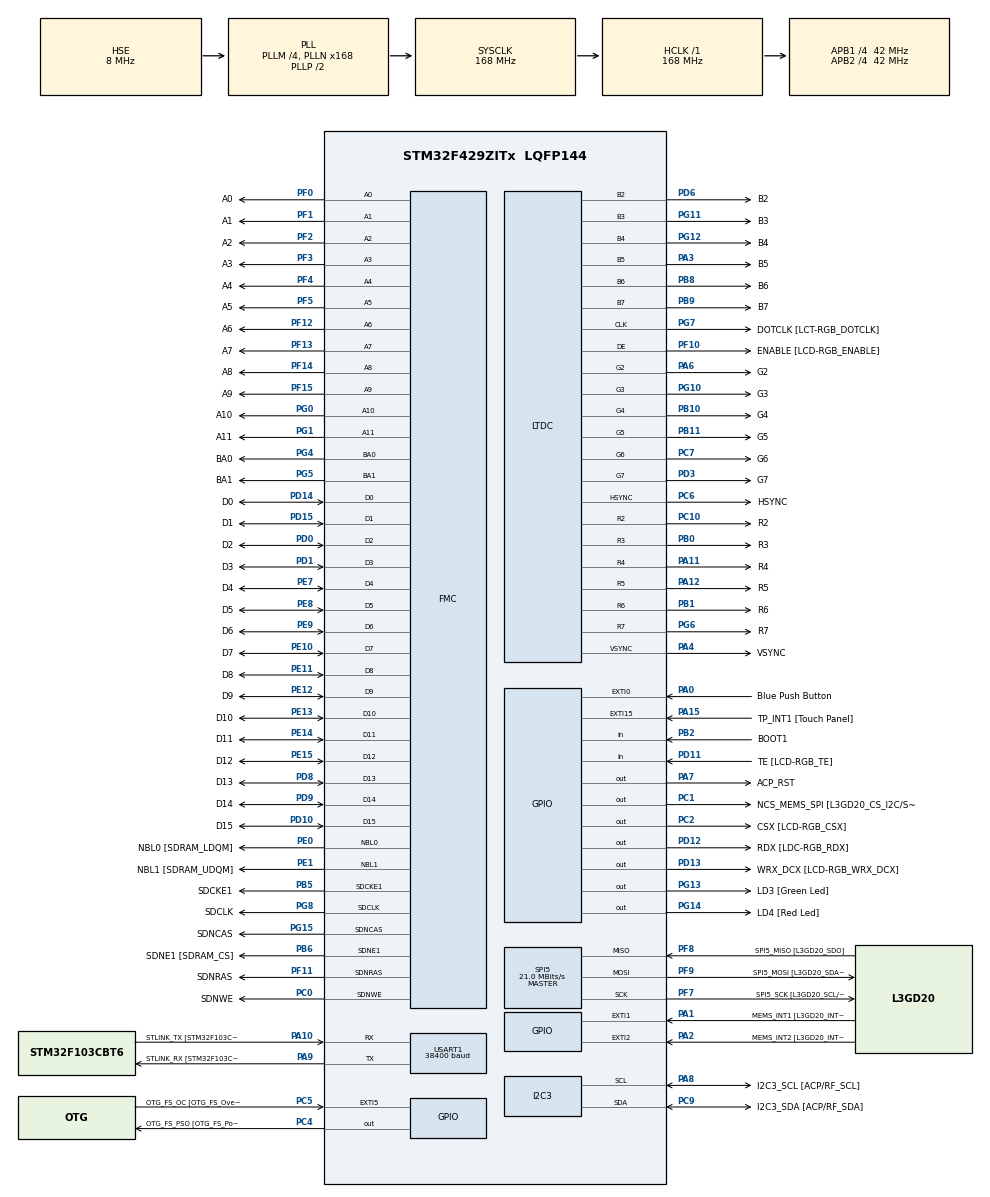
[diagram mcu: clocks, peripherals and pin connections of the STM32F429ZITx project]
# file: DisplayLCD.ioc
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DMA2D.ColorMode=DMA2D_OUTPUT_RGB565
FREERTOS.BinarySemaphores01=sensores,Dynamic,NULL;touch,Dynamic,NULL
FREERTOS.Tasks01=PrintaDisplay,0,128,StartPrintaDisplay,Default,NULL,Dynamic,NULL,NULL;MonitoraTouch,0,128,StartMonitoraTouch,Default,NULL,Dynamic,NULL,NULL
LTDC.ActiveH=240
LTDC.ActiveW=320
Mcu.Family=STM32F4
Mcu.Name=STM32F429ZITx
Mcu.Package=LQFP144
NVIC.EXTI0_IRQn=true\:5\:0\:false\:false\:true\:true\:true
NVIC.PriorityGroup=NVIC_PRIORITYGROUP_4
NVIC.TIM1_UP_TIM10_IRQn=true\:0\:0\:false\:false\:true\:false\:false
NVIC.TimeBase=TIM1_UP_TIM10_IRQn
NVIC.TimeBaseIP=TIM1
NVIC.USART1_IRQn=true\:5\:0\:false\:false\:true\:true\:true
PA0/WKUP.GPIO_Label=Blue Push Button
PA0/WKUP.GPIO_ModeDefaultEXTI=GPIO_MODE_IT_RISING
PA0/WKUP.Signal=GPXTI0
PA1.GPIO_Label=MEMS_INT1 [L3GD20_INT1]
PA1.GPIO_ModeDefaultEXTI=GPIO_MODE_EVT_RISING
PA1.GPIO_PuPd=GPIO_NOPULL
PA1.Signal=GPXTI1
PA10.GPIO_Label=STLINK_TX [STM32F103CBT6_PA2]
PA10.Mode=Asynchronous
PA10.Signal=USART1_RX
PA11.GPIO_Label=R4
PA11.GPIO_Mode=GPIO_MODE_AF_PP
PA11.GPIO_PuPd=GPIO_NOPULL
PA11.GPIO_Speed=GPIO_SPEED_FREQ_LOW
PA11.Mode=RGB666
PA11.Signal=LTDC_R4
PA12.GPIO_Label=R5
PA12.GPIO_Mode=GPIO_MODE_AF_PP
PA12.GPIO_PuPd=GPIO_NOPULL
PA12.GPIO_Speed=GPIO_SPEED_FREQ_LOW
PA12.Mode=RGB666
PA12.Signal=LTDC_R5
PA13.GPIO_Label=SWDIO
PA13.Mode=Serial_Wire
PA13.Signal=SYS_JTMS-SWDIO
PA14.GPIO_Label=SWCLK
PA14.Mode=Serial_Wire
PA14.Signal=SYS_JTCK-SWCLK
PA15.GPIO_Label=TP_INT1 [Touch Panel]
PA15.GPIO_ModeDefaultEXTI=GPIO_MODE_EVT_RISING
PA15.GPIO_PuPd=GPIO_NOPULL
PA15.Signal=GPXTI15
PA2.GPIO_Label=MEMS_INT2 [L3GD20_INT2]
PA2.GPIO_ModeDefaultEXTI=GPIO_MODE_EVT_RISING
PA2.GPIO_PuPd=GPIO_NOPULL
PA2.Signal=GPXTI2
PA3.GPIO_Label=B5
PA3.GPIO_Mode=GPIO_MODE_AF_PP
PA3.GPIO_PuPd=GPIO_NOPULL
PA3.GPIO_Speed=GPIO_SPEED_FREQ_LOW
PA3.Mode=RGB666
PA3.Signal=LTDC_B5
PA4.GPIO_Label=VSYNC
PA4.GPIO_Mode=GPIO_MODE_AF_PP
PA4.GPIO_PuPd=GPIO_NOPULL
PA4.GPIO_Speed=GPIO_SPEED_FREQ_LOW
PA4.Mode=RGB666
PA4.Signal=LTDC_VSYNC
PA6.GPIO_Label=G2
PA6.GPIO_Mode=GPIO_MODE_AF_PP
PA6.GPIO_PuPd=GPIO_NOPULL
PA6.GPIO_Speed=GPIO_SPEED_FREQ_LOW
PA6.Mode=RGB666
PA6.Signal=LTDC_G2
PA7.GPIO_Label=ACP_RST
PA7.GPIO_Mode=GPIO_MODE_OUTPUT_PP
PA7.GPIO_PuPd=GPIO_NOPULL
PA7.GPIO_Speed=GPIO_SPEED_FREQ_LOW
PA7.Signal=GPIO_Output
PA8.GPIO_Label=I2C3_SCL [ACP/RF_SCL]
PA8.GPIO_Mode=GPIO_MODE_AF_OD
PA8.GPIO_PuPd=GPIO_NOPULL
PA8.GPIO_Speed=GPIO_SPEED_FREQ_LOW
PA8.Mode=I2C
PA8.Signal=I2C3_SCL
PA9.GPIO_Label=STLINK_RX [STM32F103CBT6_PA3]
PA9.Mode=Asynchronous
PA9.Signal=USART1_TX
PB0.GPIO_Label=R3
PB0.GPIO_Mode=GPIO_MODE_AF_PP
PB0.GPIO_PuPd=GPIO_NOPULL
PB0.GPIO_Speed=GPIO_SPEED_FREQ_LOW
PB0.Mode=RGB666
PB0.Signal=LTDC_R3
PB1.GPIO_Label=R6
PB1.GPIO_Mode=GPIO_MODE_AF_PP
PB1.GPIO_PuPd=GPIO_NOPULL
PB1.GPIO_Speed=GPIO_SPEED_FREQ_LOW
PB1.Mode=RGB666
PB1.Signal=LTDC_R6
PB10.GPIO_Label=G4
PB10.GPIO_Mode=GPIO_MODE_AF_PP
PB10.GPIO_PuPd=GPIO_NOPULL
PB10.GPIO_Speed=GPIO_SPEED_FREQ_LOW
PB10.Mode=RGB666
PB10.Signal=LTDC_G4
PB11.GPIO_Label=G5
PB11.GPIO_Mode=GPIO_MODE_AF_PP
PB11.GPIO_PuPd=GPIO_NOPULL
PB11.GPIO_Speed=GPIO_SPEED_FREQ_LOW
PB11.Mode=RGB666
PB11.Signal=LTDC_G5
PB12.GPIO_Label=OTG_HS_ID
PB12.GPIO_Mode=GPIO_MODE_AF_PP
PB12.GPIO_PuPd=GPIO_NOPULL
PB12.GPIO_Speed=GPIO_SPEED_FREQ_LOW
PB12.Signal=USB_OTG_HS_ID
PB13.GPIO_Label=VBUS_HS
PB13.GPIO_Mode=GPIO_MODE_INPUT
PB13.GPIO_PuPd=GPIO_NOPULL
PB13.Signal=USB_OTG_HS_VBUS
PB14.GPIO_Label=OTG_HS_DM
PB14.GPIO_Mode=GPIO_MODE_AF_PP
PB14.GPIO_PuPd=GPIO_NOPULL
PB14.GPIO_Speed=GPIO_SPEED_FREQ_LOW
PB14.Signal=USB_OTG_HS_DM
PB15.GPIO_Label=OTG_HS_DP
PB15.GPIO_Mode=GPIO_MODE_AF_PP
PB15.GPIO_PuPd=GPIO_NOPULL
PB15.GPIO_Speed=GPIO_SPEED_FREQ_LOW
PB15.Signal=USB_OTG_HS_DP
PB2/BOOT1.GPIO_Label=BOOT1
PB2/BOOT1.GPIO_Mode=GPIO_MODE_INPUT
PB2/BOOT1.GPIO_PuPd=GPIO_NOPULL
PB2/BOOT1.Signal=GPIO_Input
PB5.GPIO_Label=SDCKE1
PB5.GPIO_Mode=GPIO_MODE_AF_PP
PB5.GPIO_PuPd=GPIO_NOPULL
PB5.GPIO_Speed=GPIO_SPEED_FREQ_VERY_HIGH
PB5.Mode=SdramChipSelect2_1
PB5.Signal=FMC_SDCKE1
PB6.GPIO_Label=SDNE1 [SDRAM_CS]
PB6.GPIO_Mode=GPIO_MODE_AF_PP
PB6.GPIO_PuPd=GPIO_NOPULL
PB6.GPIO_Speed=GPIO_SPEED_FREQ_VERY_HIGH
PB6.Mode=SdramChipSelect2_1
PB6.Signal=FMC_SDNE1
PB8.GPIO_Label=B6
PB8.GPIO_Mode=GPIO_MODE_AF_PP
PB8.GPIO_PuPd=GPIO_NOPULL
PB8.GPIO_Speed=GPIO_SPEED_FREQ_LOW
PB8.Mode=RGB666
PB8.Signal=LTDC_B6
PB9.GPIO_Label=B7
PB9.GPIO_Mode=GPIO_MODE_AF_PP
PB9.GPIO_PuPd=GPIO_NOPULL
PB9.GPIO_Speed=GPIO_SPEED_FREQ_LOW
PB9.Mode=RGB666
PB9.Signal=LTDC_B7
PC0.GPIO_Label=SDNWE
PC0.GPIO_Mode=GPIO_MODE_AF_PP
PC0.GPIO_PuPd=GPIO_NOPULL
PC0.GPIO_Speed=GPIO_SPEED_FREQ_VERY_HIGH
PC0.Signal=FMC_SDNWE
PC1.GPIO_Label=NCS_MEMS_SPI [L3GD20_CS_I2C/SPI]
PC1.GPIO_Mode=GPIO_MODE_OUTPUT_PP
PC1.GPIO_PuPd=GPIO_NOPULL
PC1.GPIO_Speed=GPIO_SPEED_FREQ_LOW
PC1.Signal=GPIO_Output
PC10.GPIO_Label=R2
PC10.GPIO_Mode=GPIO_MODE_AF_PP
PC10.GPIO_PuPd=GPIO_NOPULL
PC10.GPIO_Speed=GPIO_SPEED_FREQ_LOW
PC10.Mode=RGB666
PC10.Signal=LTDC_R2
PC14/OSC32_IN.GPIO_Label=PC14-OSC32_IN
PC14/OSC32_IN.Signal=RCC_OSC32_IN
PC15/OSC32_OUT.GPIO_Label=PC15-OSC32_OUT
PC15/OSC32_OUT.Signal=RCC_OSC32_OUT
PC2.GPIO_Label=CSX [LCD-RGB_CSX]
PC2.GPIO_Mode=GPIO_MODE_OUTPUT_PP
PC2.GPIO_PuPd=GPIO_NOPULL
PC2.GPIO_Speed=GPIO_SPEED_FREQ_LOW
PC2.Signal=GPIO_Output
PC4.GPIO_Label=OTG_FS_PSO [OTG_FS_PowerSwitchOn]
PC4.GPIO_Mode=GPIO_MODE_OUTPUT_PP
PC4.GPIO_PuPd=GPIO_NOPULL
PC4.GPIO_Speed=GPIO_SPEED_FREQ_LOW
PC4.Signal=GPIO_Output
PC5.GPIO_Label=OTG_FS_OC [OTG_FS_OverCurrent]
PC5.GPIO_ModeDefaultEXTI=GPIO_MODE_EVT_RISING
PC5.Signal=GPXTI5
PC6.GPIO_Label=HSYNC
PC6.GPIO_Mode=GPIO_MODE_AF_PP
PC6.GPIO_PuPd=GPIO_NOPULL
PC6.GPIO_Speed=GPIO_SPEED_FREQ_LOW
PC6.Mode=RGB666
PC6.Signal=LTDC_HSYNC
PC7.GPIO_Label=G6
PC7.GPIO_Mode=GPIO_MODE_AF_PP
PC7.GPIO_PuPd=GPIO_NOPULL
PC7.GPIO_Speed=GPIO_SPEED_FREQ_LOW
PC7.Mode=RGB666
PC7.Signal=LTDC_G6
PC9.GPIO_Label=I2C3_SDA [ACP/RF_SDA]
PC9.GPIO_Mode=GPIO_MODE_AF_OD
PC9.GPIO_PuPd=GPIO_NOPULL
PC9.GPIO_Speed=GPIO_SPEED_FREQ_LOW
PC9.Mode=I2C
PC9.Signal=I2C3_SDA
PD0.GPIO_Label=D2
PD0.GPIO_Mode=GPIO_MODE_AF_PP
PD0.GPIO_PuPd=GPIO_NOPULL
PD0.GPIO_Speed=GPIO_SPEED_FREQ_VERY_HIGH
PD0.Signal=FMC_D2_DA2
PD1.GPIO_Label=D3
PD1.GPIO_Mode=GPIO_MODE_AF_PP
PD1.GPIO_PuPd=GPIO_NOPULL
PD1.GPIO_Speed=GPIO_SPEED_FREQ_VERY_HIGH
PD1.Signal=FMC_D3_DA3
PD10.GPIO_Label=D15
PD10.GPIO_Mode=GPIO_MODE_AF_PP
PD10.GPIO_PuPd=GPIO_NOPULL
PD10.GPIO_Speed=GPIO_SPEED_FREQ_VERY_HIGH
PD10.Signal=FMC_D15_DA15
PD11.GPIO_Label=TE [LCD-RGB_TE]
PD11.GPIO_Mode=GPIO_MODE_INPUT
PD11.GPIO_PuPd=GPIO_NOPULL
PD11.Signal=GPIO_Input
PD12.GPIO_Label=RDX [LDC-RGB_RDX]
PD12.GPIO_Mode=GPIO_MODE_OUTPUT_PP
PD12.GPIO_PuPd=GPIO_NOPULL
PD12.GPIO_Speed=GPIO_SPEED_FREQ_LOW
PD12.Signal=GPIO_Output
PD13.GPIO_Label=WRX_DCX [LCD-RGB_WRX_DCX]
PD13.GPIO_Mode=GPIO_MODE_OUTPUT_PP
PD13.GPIO_PuPd=GPIO_NOPULL
PD13.GPIO_Speed=GPIO_SPEED_FREQ_LOW
PD13.Signal=GPIO_Output
PD14.GPIO_Label=D0
PD14.GPIO_Mode=GPIO_MODE_AF_PP
PD14.GPIO_PuPd=GPIO_NOPULL
PD14.GPIO_Speed=GPIO_SPEED_FREQ_VERY_HIGH
PD14.Signal=FMC_D0_DA0
PD15.GPIO_Label=D1
PD15.GPIO_Mode=GPIO_MODE_AF_PP
PD15.GPIO_PuPd=GPIO_NOPULL
PD15.GPIO_Speed=GPIO_SPEED_FREQ_VERY_HIGH
PD15.Signal=FMC_D1_DA1
PD3.GPIO_Label=G7
PD3.GPIO_Mode=GPIO_MODE_AF_PP
PD3.GPIO_PuPd=GPIO_NOPULL
PD3.GPIO_Speed=GPIO_SPEED_FREQ_LOW
PD3.Mode=RGB666
PD3.Signal=LTDC_G7
PD6.GPIO_Label=B2
PD6.GPIO_Mode=GPIO_MODE_AF_PP
PD6.GPIO_PuPd=GPIO_NOPULL
PD6.GPIO_Speed=GPIO_SPEED_FREQ_LOW
PD6.Mode=RGB666
PD6.Signal=LTDC_B2
PD8.GPIO_Label=D13
PD8.GPIO_Mode=GPIO_MODE_AF_PP
PD8.GPIO_PuPd=GPIO_NOPULL
PD8.GPIO_Speed=GPIO_SPEED_FREQ_VERY_HIGH
PD8.Signal=FMC_D13_DA13
PD9.GPIO_Label=D14
PD9.GPIO_Mode=GPIO_MODE_AF_PP
PD9.GPIO_PuPd=GPIO_NOPULL
PD9.GPIO_Speed=GPIO_SPEED_FREQ_VERY_HIGH
PD9.Signal=FMC_D14_DA14
PE0.GPIO_Label=NBL0 [SDRAM_LDQM]
PE0.GPIO_Mode=GPIO_MODE_AF_PP
PE0.GPIO_PuPd=GPIO_NOPULL
PE0.GPIO_Speed=GPIO_SPEED_FREQ_VERY_HIGH
PE0.Signal=FMC_NBL0
PE1.GPIO_Label=NBL1 [SDRAM_UDQM]
PE1.GPIO_Mode=GPIO_MODE_AF_PP
PE1.GPIO_PuPd=GPIO_NOPULL
PE1.GPIO_Speed=GPIO_SPEED_FREQ_VERY_HIGH
PE1.Signal=FMC_NBL1
PE10.GPIO_Label=D7
PE10.GPIO_Mode=GPIO_MODE_AF_PP
PE10.GPIO_PuPd=GPIO_NOPULL
PE10.GPIO_Speed=GPIO_SPEED_FREQ_VERY_HIGH
PE10.Signal=FMC_D7_DA7
PE11.GPIO_Label=D8
PE11.GPIO_Mode=GPIO_MODE_AF_PP
PE11.GPIO_PuPd=GPIO_NOPULL
PE11.GPIO_Speed=GPIO_SPEED_FREQ_VERY_HIGH
PE11.Signal=FMC_D8_DA8
PE12.GPIO_Label=D9
PE12.GPIO_Mode=GPIO_MODE_AF_PP
PE12.GPIO_PuPd=GPIO_NOPULL
PE12.GPIO_Speed=GPIO_SPEED_FREQ_VERY_HIGH
PE12.Signal=FMC_D9_DA9
PE13.GPIO_Label=D10
PE13.GPIO_Mode=GPIO_MODE_AF_PP
PE13.GPIO_PuPd=GPIO_NOPULL
PE13.GPIO_Speed=GPIO_SPEED_FREQ_VERY_HIGH
PE13.Signal=FMC_D10_DA10
PE14.GPIO_Label=D11
PE14.GPIO_Mode=GPIO_MODE_AF_PP
PE14.GPIO_PuPd=GPIO_NOPULL
PE14.GPIO_Speed=GPIO_SPEED_FREQ_VERY_HIGH
PE14.Signal=FMC_D11_DA11
PE15.GPIO_Label=D12
PE15.GPIO_Mode=GPIO_MODE_AF_PP
PE15.GPIO_PuPd=GPIO_NOPULL
PE15.GPIO_Speed=GPIO_SPEED_FREQ_VERY_HIGH
PE15.Signal=FMC_D12_DA12
PE7.GPIO_Label=D4
PE7.GPIO_Mode=GPIO_MODE_AF_PP
PE7.GPIO_PuPd=GPIO_NOPULL
PE7.GPIO_Speed=GPIO_SPEED_FREQ_VERY_HIGH
PE7.Signal=FMC_D4_DA4
PE8.GPIO_Label=D5
PE8.GPIO_Mode=GPIO_MODE_AF_PP
PE8.GPIO_PuPd=GPIO_NOPULL
PE8.GPIO_Speed=GPIO_SPEED_FREQ_VERY_HIGH
PE8.Signal=FMC_D5_DA5
PE9.GPIO_Label=D6
PE9.GPIO_Mode=GPIO_MODE_AF_PP
PE9.GPIO_PuPd=GPIO_NOPULL
PE9.GPIO_Speed=GPIO_SPEED_FREQ_VERY_HIGH
PE9.Signal=FMC_D6_DA6
PF0.GPIO_Label=A0
PF0.GPIO_Mode=GPIO_MODE_AF_PP
PF0.GPIO_PuPd=GPIO_NOPULL
PF0.GPIO_Speed=GPIO_SPEED_FREQ_VERY_HIGH
PF0.Signal=FMC_A0
PF1.GPIO_Label=A1
PF1.GPIO_Mode=GPIO_MODE_AF_PP
PF1.GPIO_PuPd=GPIO_NOPULL
PF1.GPIO_Speed=GPIO_SPEED_FREQ_VERY_HIGH
PF1.Signal=FMC_A1
PF10.GPIO_Label=ENABLE [LCD-RGB_ENABLE]
PF10.GPIO_Mode=GPIO_MODE_AF_PP
PF10.GPIO_PuPd=GPIO_NOPULL
PF10.GPIO_Speed=GPIO_SPEED_FREQ_LOW
PF10.Mode=RGB666
PF10.Signal=LTDC_DE
PF11.GPIO_Label=SDNRAS
PF11.GPIO_Mode=GPIO_MODE_AF_PP
PF11.GPIO_PuPd=GPIO_NOPULL
PF11.GPIO_Speed=GPIO_SPEED_FREQ_VERY_HIGH
PF11.Signal=FMC_SDNRAS
PF12.GPIO_Label=A6
PF12.GPIO_Mode=GPIO_MODE_AF_PP
PF12.GPIO_PuPd=GPIO_NOPULL
PF12.GPIO_Speed=GPIO_SPEED_FREQ_VERY_HIGH
PF12.Signal=FMC_A6
PF13.GPIO_Label=A7
PF13.GPIO_Mode=GPIO_MODE_AF_PP
PF13.GPIO_PuPd=GPIO_NOPULL
PF13.GPIO_Speed=GPIO_SPEED_FREQ_VERY_HIGH
PF13.Signal=FMC_A7
PF14.GPIO_Label=A8
PF14.GPIO_Mode=GPIO_MODE_AF_PP
PF14.GPIO_PuPd=GPIO_NOPULL
PF14.GPIO_Speed=GPIO_SPEED_FREQ_VERY_HIGH
PF14.Signal=FMC_A8
PF15.GPIO_Label=A9
PF15.GPIO_Mode=GPIO_MODE_AF_PP
PF15.GPIO_PuPd=GPIO_NOPULL
PF15.GPIO_Speed=GPIO_SPEED_FREQ_VERY_HIGH
PF15.Signal=FMC_A9
PF2.GPIO_Label=A2
PF2.GPIO_Mode=GPIO_MODE_AF_PP
PF2.GPIO_PuPd=GPIO_NOPULL
PF2.GPIO_Speed=GPIO_SPEED_FREQ_VERY_HIGH
PF2.Signal=FMC_A2
PF3.GPIO_Label=A3
PF3.GPIO_Mode=GPIO_MODE_AF_PP
PF3.GPIO_PuPd=GPIO_NOPULL
PF3.GPIO_Speed=GPIO_SPEED_FREQ_VERY_HIGH
PF3.Signal=FMC_A3
PF4.GPIO_Label=A4
PF4.GPIO_Mode=GPIO_MODE_AF_PP
PF4.GPIO_PuPd=GPIO_NOPULL
PF4.GPIO_Speed=GPIO_SPEED_FREQ_VERY_HIGH
PF4.Signal=FMC_A4
PF5.GPIO_Label=A5
PF5.GPIO_Mode=GPIO_MODE_AF_PP
PF5.GPIO_PuPd=GPIO_NOPULL
PF5.GPIO_Speed=GPIO_SPEED_FREQ_VERY_HIGH
PF5.Signal=FMC_A5
PF7.GPIO_Label=SPI5_SCK [L3GD20_SCL/SPC]
PF7.GPIO_Mode=GPIO_MODE_AF_PP
PF7.GPIO_PuPd=GPIO_NOPULL
PF7.GPIO_Speed=GPIO_SPEED_FREQ_LOW
PF7.Mode=Full_Duplex_Master
PF7.Signal=SPI5_SCK
PF8.GPIO_Label=SPI5_MISO [L3GD20_SDO]
PF8.GPIO_Mode=GPIO_MODE_AF_PP
PF8.GPIO_PuPd=GPIO_NOPULL
PF8.GPIO_Speed=GPIO_SPEED_FREQ_LOW
PF8.Mode=Full_Duplex_Master
PF8.Signal=SPI5_MISO
PF9.GPIO_Label=SPI5_MOSI [L3GD20_SDA/SDI/SDO]
PF9.GPIO_Mode=GPIO_MODE_AF_PP
PF9.GPIO_PuPd=GPIO_NOPULL
PF9.GPIO_Speed=GPIO_SPEED_FREQ_LOW
PF9.Mode=Full_Duplex_Master
PF9.Signal=SPI5_MOSI
PG0.GPIO_Label=A10
PG0.GPIO_Mode=GPIO_MODE_AF_PP
PG0.GPIO_PuPd=GPIO_NOPULL
PG0.GPIO_Speed=GPIO_SPEED_FREQ_VERY_HIGH
PG0.Signal=FMC_A10
PG1.GPIO_Label=A11
PG1.GPIO_Mode=GPIO_MODE_AF_PP
PG1.GPIO_PuPd=GPIO_NOPULL
PG1.GPIO_Speed=GPIO_SPEED_FREQ_VERY_HIGH
PG1.Signal=FMC_A11
PG10.GPIO_Label=G3
PG10.GPIO_Mode=GPIO_MODE_AF_PP
PG10.GPIO_PuPd=GPIO_NOPULL
PG10.GPIO_Speed=GPIO_SPEED_FREQ_LOW
PG10.Mode=RGB666
PG10.Signal=LTDC_G3
PG11.GPIO_Label=B3
PG11.GPIO_Mode=GPIO_MODE_AF_PP
PG11.GPIO_PuPd=GPIO_NOPULL
PG11.GPIO_Speed=GPIO_SPEED_FREQ_LOW
PG11.Mode=RGB666
PG11.Signal=LTDC_B3
PG12.GPIO_Label=B4
PG12.GPIO_Mode=GPIO_MODE_AF_PP
PG12.GPIO_PuPd=GPIO_NOPULL
PG12.GPIO_Speed=GPIO_SPEED_FREQ_LOW
PG12.Mode=RGB666
PG12.Signal=LTDC_B4
PG13.GPIO_Label=LD3 [Green Led]
PG13.GPIO_Mode=GPIO_MODE_OUTPUT_PP
PG13.GPIO_PuPd=GPIO_NOPULL
PG13.GPIO_Speed=GPIO_SPEED_FREQ_LOW
PG13.Signal=GPIO_Output
PG14.GPIO_Label=LD4 [Red Led]
PG14.GPIO_Mode=GPIO_MODE_OUTPUT_PP
PG14.GPIO_PuPd=GPIO_NOPULL
PG14.GPIO_Speed=GPIO_SPEED_FREQ_LOW
PG14.Signal=GPIO_Output
PG15.GPIO_Label=SDNCAS
PG15.GPIO_Mode=GPIO_MODE_AF_PP
PG15.GPIO_PuPd=GPIO_NOPULL
PG15.GPIO_Speed=GPIO_SPEED_FREQ_VERY_HIGH
PG15.Signal=FMC_SDNCAS
PG4.GPIO_Label=BA0
PG4.GPIO_Mode=GPIO_MODE_AF_PP
PG4.GPIO_PuPd=GPIO_NOPULL
PG4.GPIO_Speed=GPIO_SPEED_FREQ_VERY_HIGH
PG4.Signal=FMC_A14_BA0
PG5.GPIO_Label=BA1
PG5.GPIO_Mode=GPIO_MODE_AF_PP
PG5.GPIO_PuPd=GPIO_NOPULL
PG5.GPIO_Speed=GPIO_SPEED_FREQ_VERY_HIGH
PG5.Signal=FMC_A15_BA1
PG6.GPIO_Label=R7
PG6.GPIO_Mode=GPIO_MODE_AF_PP
PG6.GPIO_PuPd=GPIO_NOPULL
PG6.GPIO_Speed=GPIO_SPEED_FREQ_LOW
PG6.Mode=RGB666
PG6.Signal=LTDC_R7
PG7.GPIO_Label=DOTCLK [LCT-RGB_DOTCLK]
PG7.GPIO_Mode=GPIO_MODE_AF_PP
PG7.GPIO_PuPd=GPIO_NOPULL
PG7.GPIO_Speed=GPIO_SPEED_FREQ_LOW
PG7.Mode=RGB666
PG7.Signal=LTDC_CLK
PG8.GPIO_Label=SDCLK
PG8.GPIO_Mode=GPIO_MODE_AF_PP
PG8.GPIO_PuPd=GPIO_NOPULL
PG8.GPIO_Speed=GPIO_SPEED_FREQ_VERY_HIGH
PG8.Signal=FMC_SDCLK
PH0/OSC_IN.GPIO_Label=PH0-OSC_IN
PH0/OSC_IN.Mode=HSE-External-Oscillator
PH0/OSC_IN.Signal=RCC_OSC_IN
PH1/OSC_OUT.GPIO_Label=PH1-OSC_OUT
PH1/OSC_OUT.Mode=HSE-External-Oscillator
PH1/OSC_OUT.Signal=RCC_OSC_OUT
ProjectManager.HeapSize=0x200
ProjectManager.StackSize=0x400
ProjectManager.TargetToolchain=MDK-ARM V5
RCC.48MHZClocksFreq_Value=48000000
RCC.AHBFreq_Value=168000000
RCC.APB1CLKDivider=RCC_HCLK_DIV4
RCC.APB1Freq_Value=42000000
RCC.APB1TimFreq_Value=84000000
RCC.APB2CLKDivider=RCC_HCLK_DIV4
RCC.APB2Freq_Value=42000000
RCC.APB2TimFreq_Value=84000000
RCC.CortexFreq_Value=168000000
RCC.HCLKFreq_Value=168000000
RCC.HSE_VALUE=8000000
RCC.HSI_VALUE=16000000
RCC.LSE_VALUE=32768
RCC.PLLM=4
RCC.PLLN=168
RCC.PLLQ=7
RCC.PLLSAIN=216
RCC.PLLSourceVirtual=RCC_PLLSOURCE_HSE
RCC.SYSCLKFreq_VALUE=168000000
RCC.SYSCLKSource=RCC_SYSCLKSOURCE_PLLCLK
RCC.VCOOutputFreq_Value=336000000
SH.FMC_A0.0=FMC_A0,12b-sda1
SH.FMC_A1.0=FMC_A1,12b-sda1
SH.FMC_A10.0=FMC_A10,12b-sda1
SH.FMC_A11.0=FMC_A11,12b-sda1
SH.FMC_A14_BA0.0=FMC_BA0,FourSdramBanks1
SH.FMC_A15_BA1.0=FMC_BA1,FourSdramBanks1
SH.FMC_A2.0=FMC_A2,12b-sda1
SH.FMC_A3.0=FMC_A3,12b-sda1
SH.FMC_A4.0=FMC_A4,12b-sda1
SH.FMC_A5.0=FMC_A5,12b-sda1
SH.FMC_A6.0=FMC_A6,12b-sda1
SH.FMC_A7.0=FMC_A7,12b-sda1
SH.FMC_A8.0=FMC_A8,12b-sda1
SH.FMC_A9.0=FMC_A9,12b-sda1
SH.FMC_D0_DA0.0=FMC_D0,sd-16b-d1
SH.FMC_D10_DA10.0=FMC_D10,sd-16b-d1
SH.FMC_D11_DA11.0=FMC_D11,sd-16b-d1
SH.FMC_D12_DA12.0=FMC_D12,sd-16b-d1
SH.FMC_D13_DA13.0=FMC_D13,sd-16b-d1
SH.FMC_D14_DA14.0=FMC_D14,sd-16b-d1
SH.FMC_D15_DA15.0=FMC_D15,sd-16b-d1
SH.FMC_D1_DA1.0=FMC_D1,sd-16b-d1
SH.FMC_D2_DA2.0=FMC_D2,sd-16b-d1
SH.FMC_D3_DA3.0=FMC_D3,sd-16b-d1
SH.FMC_D4_DA4.0=FMC_D4,sd-16b-d1
SH.FMC_D5_DA5.0=FMC_D5,sd-16b-d1
SH.FMC_D6_DA6.0=FMC_D6,sd-16b-d1
SH.FMC_D7_DA7.0=FMC_D7,sd-16b-d1
SH.FMC_D8_DA8.0=FMC_D8,sd-16b-d1
SH.FMC_D9_DA9.0=FMC_D9,sd-16b-d1
SH.FMC_NBL0.0=FMC_NBL0,Sd2ByteEnable1
SH.FMC_NBL1.0=FMC_NBL1,Sd2ByteEnable1
SH.FMC_SDCLK.0=FMC_SDCLK,12b-sda1
SH.FMC_SDNCAS.0=FMC_SDNCAS,12b-sda1
SH.FMC_SDNRAS.0=FMC_SDNRAS,12b-sda1
SH.FMC_SDNWE.0=FMC_SDNWE,12b-sda1
SPI5.CalculateBaudRate=21.0 MBits/s
SPI5.Direction=SPI_DIRECTION_2LINES
SPI5.Mode=SPI_MODE_MASTER
SPI5.VirtualType=VM_MASTER
USART1.BaudRate=38400
USART1.VirtualMode=VM_ASYNC
VP_DMA2D_VS_DMA2D.Mode=DMA2D_Activate
VP_FREERTOS_VS_ENABLE.Mode=Enabled
VP_SYS_VS_tim1.Mode=TIM1
board=32F429IDISCOVERY

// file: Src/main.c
/* USER CODE BEGIN Header */
/**
  ******************************************************************************
  * @file           : main.c
  * @brief          : Main program body
  ******************************************************************************
  ** This notice applies to any and all portions of this file
  * that are not between comment pairs USER CODE BEGIN and
  * USER CODE END. Other portions of this file, whether
  * inserted by the user or by software development tools
  * are owned by their respective copyright owners.
  *
  * COPYRIGHT(c) 2019 STMicroelectronics
  *
  * Redistribution and use in source and binary forms, with or without modification,
  * are permitted provided that the following conditions are met:
  *   1. Redistributions of source code must retain the above copyright notice,
  *      this list of conditions and the following disclaimer.
  *   2. Redistributions in binary form must reproduce the above copyright notice,
  *      this list of conditions and the following disclaimer in the documentation
  *      and/or other materials provided with the distribution.
  *   3. Neither the name of STMicroelectronics nor the names of its contributors
  *      may be used to endorse or promote products derived from this software
  *      without specific prior written permission.
  *
  * THIS SOFTWARE IS PROVIDED BY THE COPYRIGHT HOLDERS AND CONTRIBUTORS "AS IS"
  * AND ANY EXPRESS OR IMPLIED WARRANTIES, INCLUDING, BUT NOT LIMITED TO, THE
  * IMPLIED WARRANTIES OF MERCHANTABILITY AND FITNESS FOR A PARTICULAR PURPOSE ARE
  * DISCLAIMED. IN NO EVENT SHALL THE COPYRIGHT HOLDER OR CONTRIBUTORS BE LIABLE
  * FOR ANY DIRECT, INDIRECT, INCIDENTAL, SPECIAL, EXEMPLARY, OR CONSEQUENTIAL
  * DAMAGES (INCLUDING, BUT NOT LIMITED TO, PROCUREMENT OF SUBSTITUTE GOODS OR
  * SERVICES; LOSS OF USE, DATA, OR PROFITS; OR BUSINESS INTERRUPTION) HOWEVER
  * CAUSED AND ON ANY THEORY OF LIABILITY, WHETHER IN CONTRACT, STRICT LIABILITY,
  * OR TORT (INCLUDING NEGLIGENCE OR OTHERWISE) ARISING IN ANY WAY OUT OF THE USE
  * OF THIS SOFTWARE, EVEN IF ADVISED OF THE POSSIBILITY OF SUCH DAMAGE.
  *
  ******************************************************************************
  */
/* USER CODE END Header */

#include "main.h"
#include "cmsis_os.h"
#include "dma2d.h"
#include "i2c.h"
#include "ltdc.h"
#include "spi.h"
#include "usart.h"
#include "gpio.h"
#include "fmc.h"

/* USER CODE BEGIN Includes */
#include "stm32f429i_discovery_lcd.h"
#include "stm32f429i_discovery_sdram.h"
#include "stm32f429i_discovery_ts.h"
#include "string.h"
/* USER CODE END Includes */

void SystemClock_Config(void);
void MX_FREERTOS_Init(void);

int main(void)
{

  /* MCU Configuration--------------------------------------------------------*/

  /* Reset of all peripherals, Initializes the Flash interface and the Systick. */
  HAL_Init();

  /* Configure the system clock */
  SystemClock_Config();

  /* Initialize all configured peripherals */
  MX_GPIO_Init();
  MX_DMA2D_Init();
  MX_I2C3_Init();
  MX_LTDC_Init();
  MX_SPI5_Init();
  MX_FMC_Init();
  MX_USART1_UART_Init();
  /* USER CODE BEGIN 2 */

	BSP_LCD_Init();
	BSP_LCD_LayerDefaultInit(LCD_BACKGROUND_LAYER,LCD_FRAME_BUFFER);
	BSP_LCD_LayerDefaultInit(LCD_FOREGROUND_LAYER,LCD_FRAME_BUFFER);
	BSP_LCD_SelectLayer(LCD_FOREGROUND_LAYER);
	BSP_LCD_DisplayOn();
	BSP_LCD_Clear(LCD_COLOR_WHITE);
	BSP_LCD_SetTextColor(LCD_COLOR_RED);
	BSP_TS_Init(240, 320);

  /* USER CODE END 2 */

  /* Call init function for freertos objects (in freertos.c) */
  MX_FREERTOS_Init();

  /* Start scheduler */
  osKernelStart();

  /* We should never get here as control is now taken by the scheduler */

  /* Infinite loop */
  while (1)
  {

    /* USER CODE BEGIN 3 */

		HAL_Delay(100);

  }
  /* USER CODE END 3 */
}

void SystemClock_Config(void)
{
  RCC_OscInitTypeDef RCC_OscInitStruct = {0};
  RCC_ClkInitTypeDef RCC_ClkInitStruct = {0};
  RCC_PeriphCLKInitTypeDef PeriphClkInitStruct = {0};

  /**Configure the main internal regulator output voltage
  */
  __HAL_RCC_PWR_CLK_ENABLE();
  __HAL_PWR_VOLTAGESCALING_CONFIG(PWR_REGULATOR_VOLTAGE_SCALE1);
  /**Initializes the CPU, AHB and APB busses clocks
  */
  RCC_OscInitStruct.OscillatorType = RCC_OSCILLATORTYPE_HSE;
  RCC_OscInitStruct.HSEState = RCC_HSE_ON;
  RCC_OscInitStruct.PLL.PLLState = RCC_PLL_ON;
  RCC_OscInitStruct.PLL.PLLSource = RCC_PLLSOURCE_HSE;
  RCC_OscInitStruct.PLL.PLLM = 4;
  RCC_OscInitStruct.PLL.PLLN = 168;
  RCC_OscInitStruct.PLL.PLLP = RCC_PLLP_DIV2;
  RCC_OscInitStruct.PLL.PLLQ = 7;
  if (HAL_RCC_OscConfig(&RCC_OscInitStruct) != HAL_OK)
  {
    Error_Handler();
  }
  /**Initializes the CPU, AHB and APB busses clocks
  */
  RCC_ClkInitStruct.ClockType = RCC_CLOCKTYPE_HCLK|RCC_CLOCKTYPE_SYSCLK
                              |RCC_CLOCKTYPE_PCLK1|RCC_CLOCKTYPE_PCLK2;
  RCC_ClkInitStruct.SYSCLKSource = RCC_SYSCLKSOURCE_PLLCLK;
  RCC_ClkInitStruct.AHBCLKDivider = RCC_SYSCLK_DIV1;
  RCC_ClkInitStruct.APB1CLKDivider = RCC_HCLK_DIV4;
  RCC_ClkInitStruct.APB2CLKDivider = RCC_HCLK_DIV4;

  if (HAL_RCC_ClockConfig(&RCC_ClkInitStruct, FLASH_LATENCY_5) != HAL_OK)
  {
    Error_Handler();
  }
  PeriphClkInitStruct.PeriphClockSelection = RCC_PERIPHCLK_LTDC;
  PeriphClkInitStruct.PLLSAI.PLLSAIN = 216;
  PeriphClkInitStruct.PLLSAI.PLLSAIR = 2;
  PeriphClkInitStruct.PLLSAIDivR = RCC_PLLSAIDIVR_2;
  if (HAL_RCCEx_PeriphCLKConfig(&PeriphClkInitStruct) != HAL_OK)
  {
    Error_Handler();
  }
}

void HAL_TIM_PeriodElapsedCallback(TIM_HandleTypeDef *htim)
{
  if (htim->Instance == TIM1) {
    HAL_IncTick();
  }
}

void Error_Handler(void)
{
}

/************************ (C) COPYRIGHT STMicroelectronics *****END OF FILE****/

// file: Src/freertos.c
/* USER CODE BEGIN Header */
/**
  ******************************************************************************
  * File Name          : freertos.c
  * Description        : Code for freertos applications
  ******************************************************************************
  * This notice applies to any and all portions of this file
  * that are not between comment pairs USER CODE BEGIN and
  * USER CODE END. Other portions of this file, whether
  * inserted by the user or by software development tools
  * are owned by their respective copyright owners.
  *
  * Copyright (c) 2019 STMicroelectronics International N.V.
  * All rights reserved.
  *
  * Redistribution and use in source and binary forms, with or without
  * modification, are permitted, provided that the following conditions are met:
  *
  * 1. Redistribution of source code must retain the above copyright notice,
  *    this list of conditions and the following disclaimer.
  * 2. Redistributions in binary form must reproduce the above copyright notice,
  *    this list of conditions and the following disclaimer in the documentation
  *    and/or other materials provided with the distribution.
  * 3. Neither the name of STMicroelectronics nor the names of other
  *    contributors to this software may be used to endorse or promote products
  *    derived from this software without specific written permission.
  * 4. This software, including modifications and/or derivative works of this
  *    software, must execute solely and exclusively on microcontroller or
  *    microprocessor devices manufactured by or for STMicroelectronics.
  * 5. Redistribution and use of this software other than as permitted under
  *    this license is void and will automatically terminate your rights under
  *    this license.
  *
  * THIS SOFTWARE IS PROVIDED BY STMICROELECTRONICS AND CONTRIBUTORS "AS IS"
  * AND ANY EXPRESS, IMPLIED OR STATUTORY WARRANTIES, INCLUDING, BUT NOT
  * LIMITED TO, THE IMPLIED WARRANTIES OF MERCHANTABILITY, FITNESS FOR A
  * PARTICULAR PURPOSE AND NON-INFRINGEMENT OF THIRD PARTY INTELLECTUAL PROPERTY
  * RIGHTS ARE DISCLAIMED TO THE FULLEST EXTENT PERMITTED BY LAW. IN NO EVENT
  * SHALL STMICROELECTRONICS OR CONTRIBUTORS BE LIABLE FOR ANY DIRECT, INDIRECT,
  * INCIDENTAL, SPECIAL, EXEMPLARY, OR CONSEQUENTIAL DAMAGES (INCLUDING, BUT NOT
  * LIMITED TO, PROCUREMENT OF SUBSTITUTE GOODS OR SERVICES; LOSS OF USE, DATA,
  * OR PROFITS; OR BUSINESS INTERRUPTION) HOWEVER CAUSED AND ON ANY THEORY OF
  * LIABILITY, WHETHER IN CONTRACT, STRICT LIABILITY, OR TORT (INCLUDING
  * NEGLIGENCE OR OTHERWISE) ARISING IN ANY WAY OUT OF THE USE OF THIS SOFTWARE,
  * EVEN IF ADVISED OF THE POSSIBILITY OF SUCH DAMAGE.
  *
  ******************************************************************************
  */
/* USER CODE END Header */

#include "FreeRTOS.h"
#include "task.h"
#include "main.h"
#include "cmsis_os.h"

/* USER CODE BEGIN Includes */

#include "stm32f429i_discovery_lcd.h"
#include "stm32f429i_discovery_sdram.h"
#include "stm32f429i_discovery_ts.h"
#include "gpio.h"
#include "usart.h"
#include "stdio.h"
#include "stdlib.h"
#include "string.h"

/* USER CODE END Includes */

/* USER CODE BEGIN Variables */

struct Control{

  uint8_t raw_data[50];
	float temp;
	float umid;
	char conectado;

  TS_StateTypeDef TsState;

	uint8_t str[50];

}c;

void parser(uint8_t * raw_data, float * temp, float * umid, char * conectado);

/* USER CODE END Variables */
osThreadId PrintaDisplayHandle;
osThreadId MonitoraTouchHandle;
osSemaphoreId sensoresHandle;
osSemaphoreId touchHandle;

/* USER CODE BEGIN FunctionPrototypes */
void HAL_UART_RxCpltCallback(UART_HandleTypeDef *huart);

/* USER CODE END FunctionPrototypes */

void StartPrintaDisplay(void const * argument);
void StartMonitoraTouch(void const * argument);

void MX_FREERTOS_Init(void); /* (MISRA C 2004 rule 8.1) */

void MX_FREERTOS_Init(void) {
  /* USER CODE BEGIN Init */

	c.temp = 0.0;
	c.umid = 0.0;
	c.conectado = 0;

  HAL_UART_Receive_IT(&huart1,c.raw_data,11);

  /* USER CODE END Init */

  /* Create the semaphores(s) */
  /* definition and creation of sensores */
  osSemaphoreDef(sensores);
  sensoresHandle = osSemaphoreCreate(osSemaphore(sensores), 1);

  /* definition and creation of touch */
  osSemaphoreDef(touch);
  touchHandle = osSemaphoreCreate(osSemaphore(touch), 1);

  /* Create the thread(s) */
  /* definition and creation of PrintaDisplay */
  osThreadDef(PrintaDisplay, StartPrintaDisplay, osPriorityNormal, 0, 128);
  PrintaDisplayHandle = osThreadCreate(osThread(PrintaDisplay), NULL);

  /* definition and creation of MonitoraTouch */
  osThreadDef(MonitoraTouch, StartMonitoraTouch, osPriorityNormal, 0, 128);
  MonitoraTouchHandle = osThreadCreate(osThread(MonitoraTouch), NULL);

  /* USER CODE BEGIN RTOS_THREADS */
  //osThreadSuspend(myTask02Handle);//suspender para n�o executar a primeira vez
	//osThreadSuspend(myTask03Handle);
  /* USER CODE END RTOS_THREADS */

}

void StartPrintaDisplay(void const * argument)
{

  /* USER CODE BEGIN StartPrintaDisplay */
  /* Infinite loop */
  for(;;)
  {
		//osSemaphoreWait(sensoresHandle, osWaitForever);
		float temperatura = c.temp;
		float umidade = c.umid;
		char conectado = c.conectado;
		//osSemaphoreRelease(sensoresHandle);

    BSP_LCD_SetFont(&Font16);

    if(conectado == 's')
    {
      BSP_LCD_DisplayStringAtLine(2,(uint8_t*)"Conectado");
    }
    else if(conectado == 'n')
    {
      BSP_LCD_DisplayStringAtLine(2,(uint8_t*)"Nao conectado");
    }

    sprintf((char*)c.str,"Temp %2.1fC",temperatura);
    BSP_LCD_DisplayStringAtLine(4,c.str);
    sprintf((char*)c.str,"Umid %2.1f%%", umidade);
    BSP_LCD_DisplayStringAtLine(5,c.str);

		BSP_LCD_DisplayStringAtLine(6,c.raw_data);

    BSP_LCD_DrawRect(70,160,100,30);
    BSP_LCD_DrawRect(70,240,100,30);
  }
  /* USER CODE END StartPrintaDisplay */
}

void StartMonitoraTouch(void const * argument)
{
  /* USER CODE BEGIN StartMonitoraTouch */
  /* Infinite loop */
  for(;;)
  {
    //osSemaphoreWait(touchHandle, osWaitForever);
    BSP_TS_GetState(&c.TsState);
    //osSemaphoreRelease(touchHandle);

    if(c.TsState.TouchDetected)
    {
      if(c.TsState.X > 70 && c.TsState.X < 170)
      {
        if(c.TsState.Y > 235 && c.TsState.Y < 275) // Botao 1
        {
          uint8_t ch = 'a';
          HAL_UART_Transmit(&huart1,&ch,1,1000);
          BSP_LCD_DisplayStringAtLine(1,(uint8_t*)"Touch Botao 1");
        }
        else if(c.TsState.Y > 155 && c.TsState.Y < 235) // Botao 2
        {
          uint8_t ch = 'f';
          HAL_UART_Transmit(&huart1,&ch,1,1000);
          BSP_LCD_DisplayStringAtLine(1,(uint8_t*)"Touch Botao 2");
        }
      }
    }
  }
  /* USER CODE END StartMonitoraTouch */
}

/* USER CODE BEGIN Application */

void HAL_UART_RxCpltCallback(UART_HandleTypeDef *huart)
{
  //osSemaphoreWait(sensoresHandle, osWaitForever);
  parser(c.raw_data, &c.temp, &c.umid, &c.conectado);
  //osSemaphoreRelease(sensoresHandle);

  HAL_UART_Receive_IT(&huart1,c.raw_data,11);
}

void parser(uint8_t * raw_data, float * temp, float * umid, char * conectado)
{
  char t[4];
  t[0] = raw_data[0];
  t[1] = raw_data[1];
  t[2] = raw_data[2];
  t[3] = raw_data[3];
  *temp = strtod(t, NULL);

  char u[4];
  u[0] = raw_data[5];
  u[1] = raw_data[6];
  u[2] = raw_data[7];
  u[3] = raw_data[8];
  *umid = strtod(u, NULL);

  char c;
  c = raw_data[10];
  *conectado = c;
}

/* USER CODE END Application */

/************************ (C) COPYRIGHT STMicroelectronics *****END OF FILE****/
